VERSION ""

NS_ :

BS_:

BU_:

BO_ 16 message_1: 4 Vector__XXX
 SG_ signal_2 : 24|8@1+ (1,0) [0|255] "" Vector__XXX
 SG_ signal1 : 0|24@1- (1,0) [-8.38861e+006|8.38861e+006] "" Vector__XXX

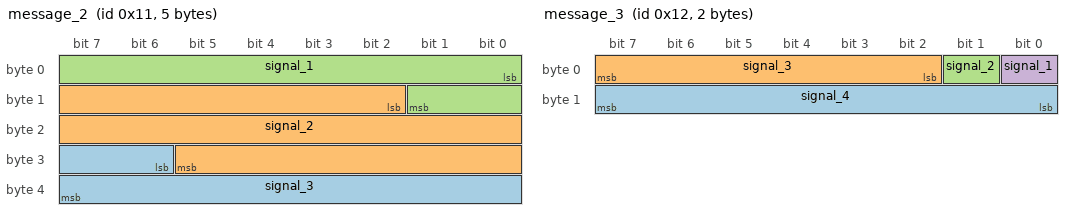
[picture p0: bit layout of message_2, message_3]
BO_ 17 message_2: 5 Vector__XXX
 SG_ signal_3 : 30|10@1- (0.25,0) [-128|127.75] "" Vector__XXX
 SG_ signal_2 : 10|20@1+ (1,0) [0|1.04858e+006] "" Vector__XXX
 SG_ signal_1 : 0|10@1+ (1,0) [0|1023] "" Vector__XXX

BO_ 18 message_3: 2 Vector__XXX
 SG_ signal_4 : 8|8@1- (10,0) [-1280|1270] "m/s" Vector__XXX
 SG_ signal_3 : 2|6@1- (0.75,0) [-24|23.25] "" Vector__XXX
 SG_ signal_2 : 1|1@1- (1,0) [0|1] "" Vector__XXX
 SG_ signal_1 : 0|1@1- (1,0) [0|1] "" Vector__XXX
